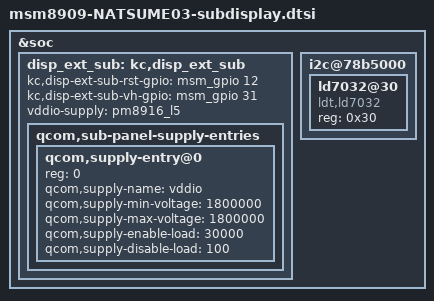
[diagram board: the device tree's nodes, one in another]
/*
 * This software is contributed or developed by KYOCERA Corporation.
 * (C) 2019 KYOCERA Corporation
 *
 * This program is free software; you can redistribute it and/or modify
 * it under the terms of the GNU General Public License version 2 and
 * only version 2 as published by the Free Software Foundation.
 *
 * This program is distributed in the hope that it will be useful,
 * but WITHOUT ANY WARRANTY; without even the implied warranty of
 * MERCHANTABILITY or FITNESS FOR A PARTICULAR PURPOSE.  See the
 * GNU General Public License for more details.
 */

#include "panel-kc-pioneer-092inch.dtsi"

&soc {
	disp_ext_sub: kc,disp_ext_sub {
		kc,disp-ext-sub-rst-gpio = <&msm_gpio 12 0>;
		kc,disp-ext-sub-vh-gpio = <&msm_gpio 31 0>;
		
		vddio-supply = <&pm8916_l5>;

		qcom,sub-panel-supply-entries {
			#address-cells = <1>;
			#size-cells = <0>;

			qcom,supply-entry@0 {
				reg = <0>;
				qcom,supply-name = "vddio";
				qcom,supply-min-voltage = <1800000>;
				qcom,supply-max-voltage = <1800000>;
				qcom,supply-enable-load = <30000>;
				qcom,supply-disable-load = <100>;
			};
		};
	};

	i2c@78b5000 {
		ld7032@30 {
			compatible = "ldt,ld7032";
			reg = <0x30>;
		};
	};

};
